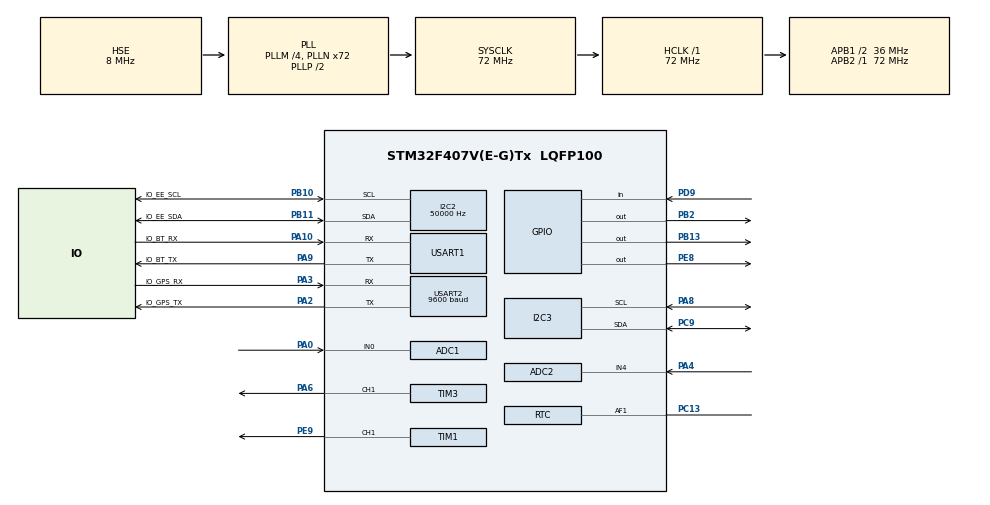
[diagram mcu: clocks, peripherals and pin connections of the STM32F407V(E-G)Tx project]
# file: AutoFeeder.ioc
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ADC1.Channel-0\#ChannelRegularConversion=ADC_CHANNEL_0
ADC1.ContinuousConvMode=ENABLE
ADC1.NbrOfConversion=1
ADC1.NbrOfConversionFlag=1
ADC1.Rank-0\#ChannelRegularConversion=1
ADC1.SamplingTime-0\#ChannelRegularConversion=ADC_SAMPLETIME_3CYCLES
ADC1.master=1
ADC2.Channel-0\#ChannelRegularConversion=ADC_CHANNEL_4
ADC2.Channel-1\#ChannelRegularConversion=ADC_CHANNEL_4
ADC2.Channel-2\#ChannelRegularConversion=ADC_CHANNEL_4
ADC2.Channel-3\#ChannelRegularConversion=ADC_CHANNEL_4
ADC2.ContinuousConvMode=ENABLE
ADC2.NbrOfConversion=4
ADC2.NbrOfConversionFlag=1
ADC2.Rank-0\#ChannelRegularConversion=1
ADC2.Rank-1\#ChannelRegularConversion=2
ADC2.Rank-2\#ChannelRegularConversion=3
ADC2.Rank-3\#ChannelRegularConversion=4
ADC2.SamplingTime-0\#ChannelRegularConversion=ADC_SAMPLETIME_3CYCLES
ADC2.SamplingTime-1\#ChannelRegularConversion=ADC_SAMPLETIME_3CYCLES
ADC2.SamplingTime-2\#ChannelRegularConversion=ADC_SAMPLETIME_3CYCLES
ADC2.SamplingTime-3\#ChannelRegularConversion=ADC_SAMPLETIME_3CYCLES
I2C2.ClockSpeed=50000
I2C2.OwnAddress=0x50
IWDG.Prescaler=IWDG_PRESCALER_64
IWDG.Reload=1249
Mcu.Family=STM32F4
Mcu.Name=STM32F407V(E-G)Tx
Mcu.Package=LQFP100
NVIC.ADC_IRQn=true\:0\:0\:false\:false\:true\:true\:true\:true
NVIC.PriorityGroup=NVIC_PRIORITYGROUP_2
NVIC.TAMP_STAMP_IRQn=true\:0\:0\:false\:false\:true\:true\:true\:true
NVIC.TIM1_UP_TIM10_IRQn=true\:0\:0\:false\:false\:true\:true\:true\:true
NVIC.TIM4_IRQn=true\:3\:0\:false\:false\:true\:false\:true\:true
NVIC.TimeBase=TIM4_IRQn
NVIC.TimeBaseIP=TIM4
NVIC.USART1_IRQn=true\:0\:0\:false\:false\:true\:true\:true\:true
NVIC.USART2_IRQn=true\:0\:0\:false\:false\:true\:true\:true\:true
PA0-WKUP.GPIO_Mode=GPIO_MODE_ANALOG
PA0-WKUP.Signal=ADCx_IN0
PA10.GPIO_Label=IO_BT_RX
PA10.GPIO_ModeDefaultPP=GPIO_MODE_AF_OD
PA10.GPIO_Speed=GPIO_SPEED_FREQ_HIGH
PA10.Mode=Asynchronous
PA10.Signal=USART1_RX
PA13.Mode=Serial_Wire
PA13.Signal=SYS_JTMS-SWDIO
PA14.Mode=Serial_Wire
PA14.Signal=SYS_JTCK-SWCLK
PA15.GPIO_Mode=GPIO_MODE_AF_PP
PA15.GPIO_PuPd=GPIO_NOPULL
PA15.GPIO_Speed=GPIO_SPEED_FREQ_HIGH
PA15.Signal=I2S3_WS
PA2.GPIO_Label=IO_GPS_TX
PA2.GPIO_Speed=GPIO_SPEED_FREQ_HIGH
PA2.Mode=Asynchronous
PA2.Signal=USART2_TX
PA3.GPIO_Label=IO_GPS_RX
PA3.GPIO_ModeDefaultPP=GPIO_MODE_AF_OD
PA3.GPIO_PuPd=GPIO_NOPULL
PA3.GPIO_Speed=GPIO_SPEED_FREQ_HIGH
PA3.Mode=Asynchronous
PA3.Signal=USART2_RX
PA4.GPIO_Mode=GPIO_MODE_ANALOG
PA4.Signal=ADCx_IN4
PA6.GPIO_Speed=GPIO_SPEED_FREQ_HIGH
PA6.Signal=S_TIM3_CH1
PA8.GPIO_Speed=GPIO_SPEED_FREQ_HIGH
PA8.Mode=I2C
PA8.Signal=I2C3_SCL
PA9.GPIO_Label=IO_BT_TX
PA9.GPIO_ModeDefaultPP=GPIO_MODE_AF_OD
PA9.GPIO_Speed=GPIO_SPEED_FREQ_HIGH
PA9.Mode=Asynchronous
PA9.Signal=USART1_TX
PB10.GPIO_Label=IO_EE_SCL
PB10.GPIO_Speed=GPIO_SPEED_FREQ_HIGH
PB10.Mode=I2C
PB10.Signal=I2C2_SCL
PB11.GPIO_Label=IO_EE_SDA
PB11.GPIO_Speed=GPIO_SPEED_FREQ_HIGH
PB11.Mode=I2C
PB11.Signal=I2C2_SDA
PB13.PinState=GPIO_PIN_SET
PB13.Signal=GPIO_Output
PB14.GPIO_Speed=GPIO_SPEED_FREQ_HIGH
PB14.Signal=S_TIM12_CH1
PB2.GPIO_Speed=GPIO_SPEED_FREQ_LOW
PB2.Signal=GPIO_Output
PB7.GPIO_Speed=GPIO_SPEED_FREQ_HIGH
PB7.Signal=DCMI_VSYNC
PC10.GPIO_Speed=GPIO_SPEED_FREQ_HIGH
PC10.Signal=I2S3_CK
PC12.GPIO_Speed=GPIO_SPEED_FREQ_HIGH
PC12.Signal=I2S3_SD
PC13-ANTI_TAMP.Mode=Tamper 1 enabled - Input Enabled to AF1
PC13-ANTI_TAMP.Signal=RTC_AF1
PC14-OSC32_IN.GPIO_Label=PC14_OSC32_IN
PC14-OSC32_IN.Mode=LSE-External-Oscillator
PC14-OSC32_IN.Signal=RCC_OSC32_IN
PC15-OSC32_OUT.GPIO_Label=PC15_OSC32_OUT
PC15-OSC32_OUT.Mode=LSE-External-Oscillator
PC15-OSC32_OUT.Signal=RCC_OSC32_OUT
PC9.GPIO_Speed=GPIO_SPEED_FREQ_HIGH
PC9.Mode=I2C
PC9.Signal=I2C3_SDA
PD9.GPIO_Mode=GPIO_MODE_INPUT
PD9.Signal=GPIO_Input
PE8.GPIO_Speed=GPIO_SPEED_FREQ_LOW
PE8.Signal=GPIO_Output
PE9.GPIO_Speed=GPIO_SPEED_FREQ_HIGH
PE9.Signal=S_TIM1_CH1
PH0-OSC_IN.GPIO_Label=PH0_OSC_IN
PH0-OSC_IN.Mode=HSE-External-Oscillator
PH0-OSC_IN.Signal=RCC_OSC_IN
PH1-OSC_OUT.GPIO_Label=PH1_OSC_OUT
PH1-OSC_OUT.Mode=HSE-External-Oscillator
PH1-OSC_OUT.Signal=RCC_OSC_OUT
ProjectManager.HeapSize=0x200
ProjectManager.StackSize=0x400
ProjectManager.TargetToolchain=MDK-ARM V5.32
RCC.48MHZClocksFreq_Value=36000000
RCC.AHBFreq_Value=72000000
RCC.APB1CLKDivider=RCC_HCLK_DIV2
RCC.APB1Freq_Value=36000000
RCC.APB1TimFreq_Value=72000000
RCC.APB2Freq_Value=72000000
RCC.APB2TimFreq_Value=72000000
RCC.CortexFreq_Value=72000000
RCC.HCLKFreq_Value=72000000
RCC.HSE_VALUE=8000000
RCC.HSI_VALUE=16000000
RCC.PLLM=4
RCC.PLLN=72
RCC.PLLSourceVirtual=RCC_PLLSOURCE_HSE
RCC.RCC_RTC_Clock_Source=RCC_RTCCLKSOURCE_LSE
RCC.RCC_RTC_Clock_SourceVirtual=RCC_RTCCLKSOURCE_LSE
RCC.SYSCLKFreq_VALUE=72000000
RCC.SYSCLKSource=RCC_SYSCLKSOURCE_PLLCLK
RCC.VCOOutputFreq_Value=144000000
RTC.PinSelection_1=RTC_TAMPERPIN_DEFAULT
SH.ADCx_IN0.0=ADC1_IN0,IN0
SH.ADCx_IN4.0=ADC2_IN4,IN4
SH.S_TIM12_CH1.0=TIM12_CH1
SH.S_TIM1_CH1.0=TIM1_CH1,PWM Generation1 CH1
SH.S_TIM3_CH1.0=TIM3_CH1,PWM Generation1 CH1
TIM1.Channel-PWM\ Generation1\ CH1=TIM_CHANNEL_1
TIM1.Period=199
TIM1.Prescaler=7199
TIM3.Channel-PWM\ Generation1\ CH1=TIM_CHANNEL_1
USART1.VirtualMode=VM_ASYNC
USART2.BaudRate=9600
USART2.VirtualMode=VM_ASYNC
VP_IWDG_VS_IWDG.Mode=IWDG_Activate
VP_RTC_VS_RTC_Activate.Mode=RTC_Enabled
VP_SYS_VS_tim4.Mode=TIM4
VP_TIM1_VS_ClockSourceINT.Mode=Internal
board=custom

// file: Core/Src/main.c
/* USER CODE BEGIN Header */
/**
  ******************************************************************************
  * @file           : main.c
  * @brief          : Main program body
  ******************************************************************************
  * @attention
  *
  * Copyright (c) 2024 STMicroelectronics.
  * All rights reserved.
  *
  * This software is licensed under terms that can be found in the LICENSE file
  * in the root directory of this software component.
  * If no LICENSE file comes with this software, it is provided AS-IS.
  *
  ******************************************************************************
  */
/* USER CODE END Header */
#include "main.h"
#include "adc.h"
#include "i2c.h"
#include "iwdg.h"
#include "rtc.h"
#include "tim.h"
#include "usart.h"
#include "gpio.h"

void SystemClock_Config(void);

int main(void)
{

  /* MCU Configuration--------------------------------------------------------*/

  /* Reset of all peripherals, Initializes the Flash interface and the Systick. */
  HAL_Init();

  /* Configure the system clock */
  SystemClock_Config();

  /* Initialize all configured peripherals */
  MX_GPIO_Init();
  MX_I2C2_Init();
  MX_IWDG_Init();
  MX_TIM1_Init();
  MX_TIM3_Init();
  MX_USART1_UART_Init();
  MX_USART2_UART_Init();
  MX_ADC1_Init();
  MX_ADC2_Init();
  MX_I2C3_Init();
  MX_RTC_Init();

  /* Infinite loop */
  while (1)
  {

    /* USER CODE BEGIN 3 */
    //UART2串口进行回调串口2的接收
  }
  /* USER CODE END 3 */
}

void SystemClock_Config(void)
{
  RCC_OscInitTypeDef RCC_OscInitStruct = {0};
  RCC_ClkInitTypeDef RCC_ClkInitStruct = {0};

  /** Configure the main internal regulator output voltage
  */
  __HAL_RCC_PWR_CLK_ENABLE();
  __HAL_PWR_VOLTAGESCALING_CONFIG(PWR_REGULATOR_VOLTAGE_SCALE1);

  /** Initializes the RCC Oscillators according to the specified parameters
  * in the RCC_OscInitTypeDef structure.
  */
  RCC_OscInitStruct.OscillatorType = RCC_OSCILLATORTYPE_LSI|RCC_OSCILLATORTYPE_HSE
                              |RCC_OSCILLATORTYPE_LSE;
  RCC_OscInitStruct.HSEState = RCC_HSE_ON;
  RCC_OscInitStruct.LSEState = RCC_LSE_ON;
  RCC_OscInitStruct.LSIState = RCC_LSI_ON;
  RCC_OscInitStruct.PLL.PLLState = RCC_PLL_ON;
  RCC_OscInitStruct.PLL.PLLSource = RCC_PLLSOURCE_HSE;
  RCC_OscInitStruct.PLL.PLLM = 4;
  RCC_OscInitStruct.PLL.PLLN = 72;
  RCC_OscInitStruct.PLL.PLLP = RCC_PLLP_DIV2;
  RCC_OscInitStruct.PLL.PLLQ = 4;
  if (HAL_RCC_OscConfig(&RCC_OscInitStruct) != HAL_OK)
  {
    Error_Handler();
  }

  /** Initializes the CPU, AHB and APB buses clocks
  */
  RCC_ClkInitStruct.ClockType = RCC_CLOCKTYPE_HCLK|RCC_CLOCKTYPE_SYSCLK
                              |RCC_CLOCKTYPE_PCLK1|RCC_CLOCKTYPE_PCLK2;
  RCC_ClkInitStruct.SYSCLKSource = RCC_SYSCLKSOURCE_PLLCLK;
  RCC_ClkInitStruct.AHBCLKDivider = RCC_SYSCLK_DIV1;
  RCC_ClkInitStruct.APB1CLKDivider = RCC_HCLK_DIV2;
  RCC_ClkInitStruct.APB2CLKDivider = RCC_HCLK_DIV1;

  if (HAL_RCC_ClockConfig(&RCC_ClkInitStruct, FLASH_LATENCY_2) != HAL_OK)
  {
    Error_Handler();
  }
}

void HAL_TIM_PeriodElapsedCallback(TIM_HandleTypeDef *htim)
{
  if (htim->Instance == TIM4) {
    HAL_IncTick();
  }
}

void Error_Handler(void)
{
  __disable_irq();
  while (1)
  {
  }
}
